# f280015x_nwreg_regs register map
Vendor: Texas Instruments
Peripheral module from a debugger description file (folder C2000).
Address unit: 16 bits
Registers are 32-bit, read-write, no defined reset value unless marked. A register's access mark holds for its fields unless they carry their own. Offsets are as the file gives them; lines under a group give offsets from that group; [hi:lo] are bit positions; {n}, {i} and the like mark numbered series; 'fields as' and 'values as' point back to an identical list; <NAME> marks a mode.

## NWREG — NWREG Registers
0x10 IIDX ro — Interrupt Index Register
  [0] STAT — STAT bit field
0x14 IMASK — Interrupt Mask Register
  [0] DONE — DONE bit field
0x18 RIS ro — Raw Interrupt Status Register
  [0] DONE — DONE bit field
0x1C MIS ro — Masked Interrupt Status Register
  [0] DONE — DONE bit field
0x20 ISET — Interrupt Set Register
  [0] DONE — DONE bit field
0x24 ICLR — Interrupt Clear Register
  [0] DONE — DONE bit field
0x70 EVT_MODE ro — Event Mode
  [1:0] INT0_CFG — INT0_CFG bit field
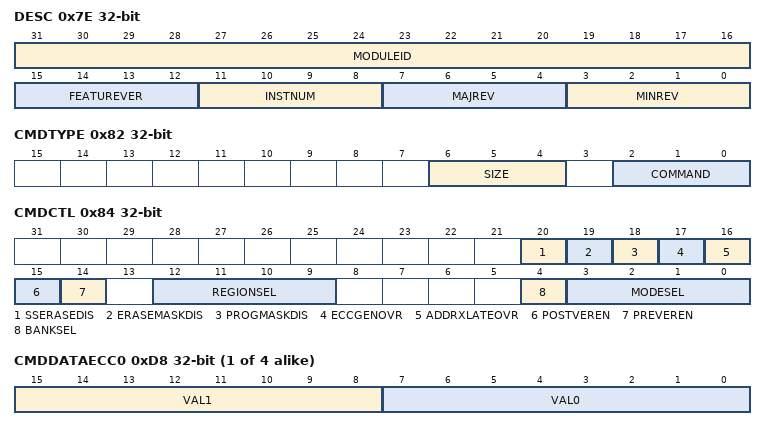
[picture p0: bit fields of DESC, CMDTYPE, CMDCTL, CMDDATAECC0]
0x7E DESC ro
  [31:16] MODULEID — MODULEID bit field
  [15:12] FEATUREVER — FEATUREVER bit field
  [11:8] INSTNUM — INSTNUM bit field
  [7:4] MAJREV — MAJREV bit field
  [3:0] MINREV — MINREV bit field
0x80 CMDEXEC — Command Execute Register
  [0] VAL — VAL bit field
0x82 CMDTYPE
  [6:4] SIZE — SIZE bit field
  [2:0] COMMAND — COMMAND bit field
0x84 CMDCTL
  [20] SSERASEDIS — SSERASEDIS bit field
  [19] ERASEMASKDIS — ERASEMASKDIS bit field
  [18] PROGMASKDIS — PROGMASKDIS bit field
  [17] ECCGENOVR — ECCGENOVR bit field
  [16] ADDRXLATEOVR — ADDRXLATEOVR bit field
  [15] POSTVEREN — POSTVEREN bit field
  [14] PREVEREN — PREVEREN bit field
  [12:9] REGIONSEL — REGIONSEL bit field
  [4] BANKSEL — BANKSEL bit field
  [3:0] MODESEL — MODESEL bit field
0x90 CMDADDR — Command Address Register
  [31:0] VAL — VAL bit field
0x92 CMDBYTEN — Command Program Byte Enable Register
  [17:0] VAL — VAL bit field
0x96 CMDDATAINDEX — Command Data Index Register
  [2:0] VAL — VAL bit field
{0x98+2i} CMDDATA{i} (i=0..2) — Command Data Register {i}
  [31:0] VAL — VAL bit field
0x9E CMDDATA3 — Command Data Register Bits 127:96
  [31:0] VAL — VAL bit field
{0x98+2i} CMDDATA{i} (i=4..15) — Command Data Register {i}
  [31:0] VAL — VAL bit field
{0xD8+2i} CMDDATAECC{i} (i=0..3)
  [15:8] VAL1 — VAL1 bit field
  [7:0] VAL0 — VAL0 bit field
0xE8 CMDWEPROTA — Command Write Erase Protect A Register
  [31:0] VAL — VAL bit field
0xEA CMDWEPROTB — Command Write Erase Protect B Register
  [31:0] VAL — VAL bit field
0x108 CMDWEPROTNM — Command Write Erase Protect Non-Main Register
  [31:0] VAL — VAL bit field
0x10A CMDWEPROTTR — Command Write Erase Protect Trim Register
  [2:0] VAL — VAL bit field
0x10C CMDWEPROTEN — Command Write Erase Protect Engr Register
  [31:0] VAL — VAL bit field
0x1D8 CFGCMD — Command Configuration Register
  [3:0] WAITSTATE — WAITSTATE bit field
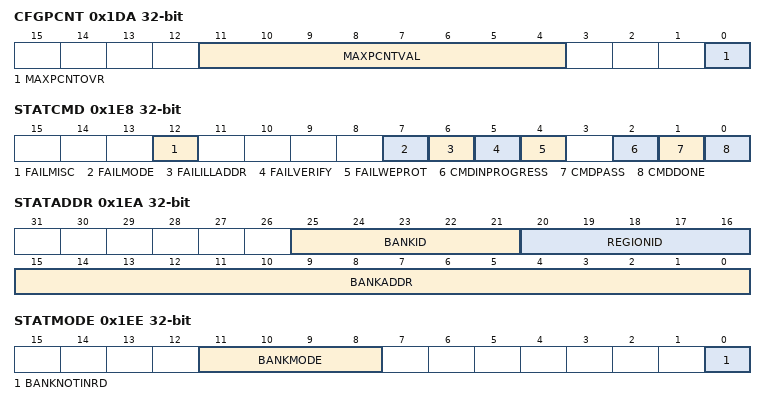
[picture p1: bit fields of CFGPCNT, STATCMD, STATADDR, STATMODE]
0x1DA CFGPCNT
  [11:4] MAXPCNTVAL — MAXPCNTVAL bit field
  [0] MAXPCNTOVR — MAXPCNTOVR bit field
0x1E8 STATCMD ro
  [12] FAILMISC — FAILMISC bit field
  [7] FAILMODE — FAILMODE bit field
  [6] FAILILLADDR — FAILILLADDR bit field
  [5] FAILVERIFY — FAILVERIFY bit field
  [4] FAILWEPROT — FAILWEPROT bit field
  [2] CMDINPROGRESS — CMDINPROGRESS bit field
  [1] CMDPASS — CMDPASS bit field
  [0] CMDDONE — CMDDONE bit field
0x1EA STATADDR ro
  [25:21] BANKID — BANKID bit field
  [20:16] REGIONID — REGIONID bit field
  [15:0] BANKADDR — BANKADDR bit field
0x1EC STATPCNT ro — Pulse Count Status Register
  [11:0] PULSECNT — PULSECNT bit field
0x1EE STATMODE ro
  [11:8] BANKMODE — BANKMODE bit field
  [0] BANKNOTINRD — BANKNOTINRD bit field
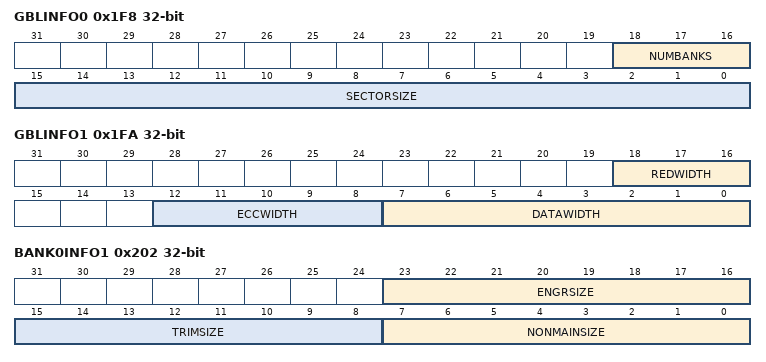
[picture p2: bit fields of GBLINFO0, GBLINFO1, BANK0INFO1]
0x1F8 GBLINFO0 ro
  [18:16] NUMBANKS — NUMBANKS bit field
  [15:0] SECTORSIZE — SECTORSIZE bit field
0x1FA GBLINFO1 ro
  [18:16] REDWIDTH — REDWIDTH bit field
  [12:8] ECCWIDTH — ECCWIDTH bit field
  [7:0] DATAWIDTH — DATAWIDTH bit field
0x200 BANK0INFO0 ro — Bank Information Register 0 for Bank 0
  [11:0] MAINSIZE — MAINSIZE bit field
0x202 BANK0INFO1 ro
  [23:16] ENGRSIZE — ENGRSIZE bit field
  [15:8] TRIMSIZE — TRIMSIZE bit field
  [7:0] NONMAINSIZE — NONMAINSIZE bit field
0x318 BANK0TRIM0
  [31:0] VAL — VAL bit field
0x31A BANK0TRIM1
  [3:0] VAL — VAL bit field
